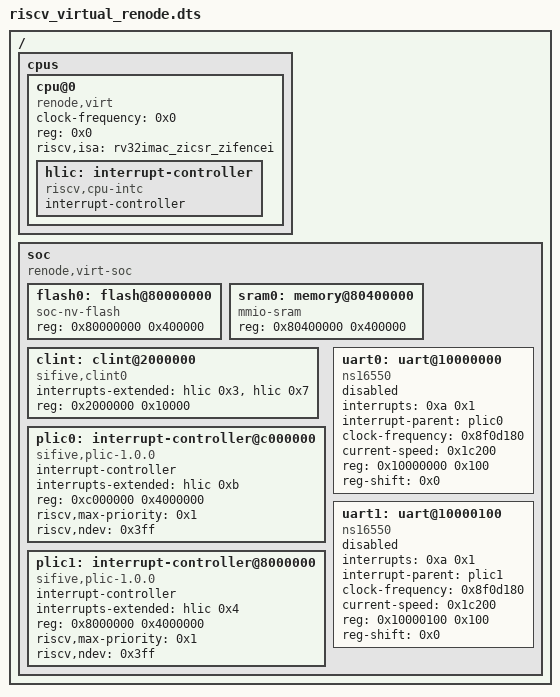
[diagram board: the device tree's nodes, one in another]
/dts-v1/;

/ {
	#address-cells = < 0x1 >;
	#size-cells = < 0x1 >;
	cpus {
		#address-cells = < 0x1 >;
		#size-cells = < 0x0 >;
		cpu@0 {
			clock-frequency = < 0x0 >;
			compatible = "renode,virt", "riscv";
			device_type = "cpu";
			reg = < 0x0 >;
			riscv,isa = "rv32imac_zicsr_zifencei";
			hlic: interrupt-controller {
				compatible = "riscv,cpu-intc";
				#address-cells = < 0x0 >;
				#interrupt-cells = < 0x1 >;
				interrupt-controller;
				phandle = < 0x1 >;
			};
		};
	};
	soc {
		#address-cells = < 0x1 >;
		#size-cells = < 0x1 >;
		compatible = "renode,virt-soc", "simple-bus";
		ranges;
		flash0: flash@80000000 {
			compatible = "soc-nv-flash";
			reg = < 0x80000000 0x400000 >;
		};
		sram0: memory@80400000 {
			compatible = "mmio-sram";
			reg = < 0x80400000 0x400000 >;
		};
		clint: clint@2000000 {
			compatible = "sifive,clint0";
			interrupts-extended = < &hlic 0x3 >, < &hlic 0x7 >;
			reg = < 0x2000000 0x10000 >;
		};
		plic0: interrupt-controller@c000000 {
			compatible = "sifive,plic-1.0.0";
			#address-cells = < 0x0 >;
			#interrupt-cells = < 0x2 >;
			interrupt-controller;
			interrupts-extended = < &hlic 0xb >;
			reg = < 0xc000000 0x4000000 >;
			riscv,max-priority = < 0x1 >;
			riscv,ndev = < 0x3ff >;
			phandle = < 0x2 >;
		};
		plic1: interrupt-controller@8000000 {
			compatible = "sifive,plic-1.0.0";
			#address-cells = < 0x0 >;
			#interrupt-cells = < 0x2 >;
			interrupt-controller;
			interrupts-extended = < &hlic 0x4 >;
			reg = < 0x8000000 0x4000000 >;
			riscv,max-priority = < 0x1 >;
			riscv,ndev = < 0x3ff >;
			phandle = < 0x3 >;
		};
		uart0: uart@10000000 {
			interrupts = < 0xa 0x1 >;
			interrupt-parent = < &plic0 >;
			clock-frequency = < 0x8f0d180 >;
			current-speed = < 0x1c200 >;
			reg = < 0x10000000 0x100 >;
			compatible = "ns16550";
			reg-shift = < 0x0 >;
			status = "disabled";
		};
		uart1: uart@10000100 {
			interrupts = < 0xa 0x1 >;
			interrupt-parent = < &plic1 >;
			clock-frequency = < 0x8f0d180 >;
			current-speed = < 0x1c200 >;
			reg = < 0x10000100 0x100 >;
			compatible = "ns16550";
			reg-shift = < 0x0 >;
			status = "disabled";
		};
	};
};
